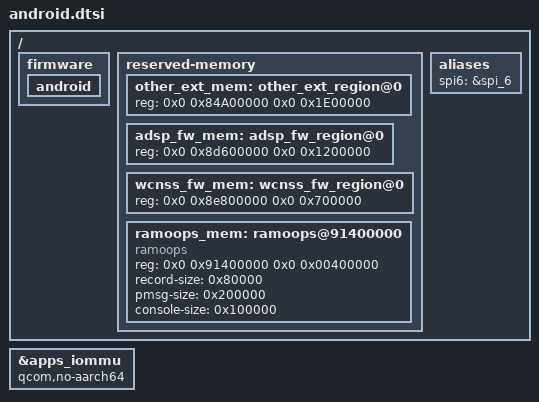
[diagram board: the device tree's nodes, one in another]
/*
 * Tissot (Xiaomi Mi A1 / tissot_sprout) android.dtsi
 *
 * Tissot uses A/B seamless updates (no recovery partition).
 * First-stage init handles all partition mounting via fstab.qcom,
 * so we delete the kernel fstab node entirely.
 *
 * Reserved memory regions and ramoops ported from:
 *   kernel/xiaomi/msm8953/arch/arm64/boot/dts/qcom/xiaomi/tissot/
 *   msm8953-tissot.dtsi (msm8953-qrd-sku3-tissot.dtsi)
 *
 * Copyright (c) 2015-2017, The Linux Foundation. All rights reserved.
 */

/ {
	firmware: firmware {
		android {
			/delete-node/ fstab;
			/delete-node/ vbmeta;
		};
	};

	reserved-memory {
		other_ext_mem: other_ext_region@0 {
			reg = <0x0 0x84A00000 0x0 0x1E00000>;
		};

		adsp_fw_mem: adsp_fw_region@0 {
			reg = <0x0 0x8d600000 0x0 0x1200000>;
		};

		wcnss_fw_mem: wcnss_fw_region@0 {
			reg = <0x0 0x8e800000 0x0 0x700000>;
		};

		/* ramoops: kernel log persistence across reboots.
		 * 4MB at 0x91400000 — allows grabbing last_kmsg after bootloop.
		 */
		ramoops_mem: ramoops@91400000 {
			compatible = "ramoops";
			reg = <0x0 0x91400000 0x0 0x00400000>;
			record-size = <0x80000>;
			pmsg-size = <0x200000>;
			console-size = <0x100000>;
		};
	};

	aliases {
		spi6 = &spi_6;
	};
};

&apps_iommu {
	qcom,no-aarch64;
};
